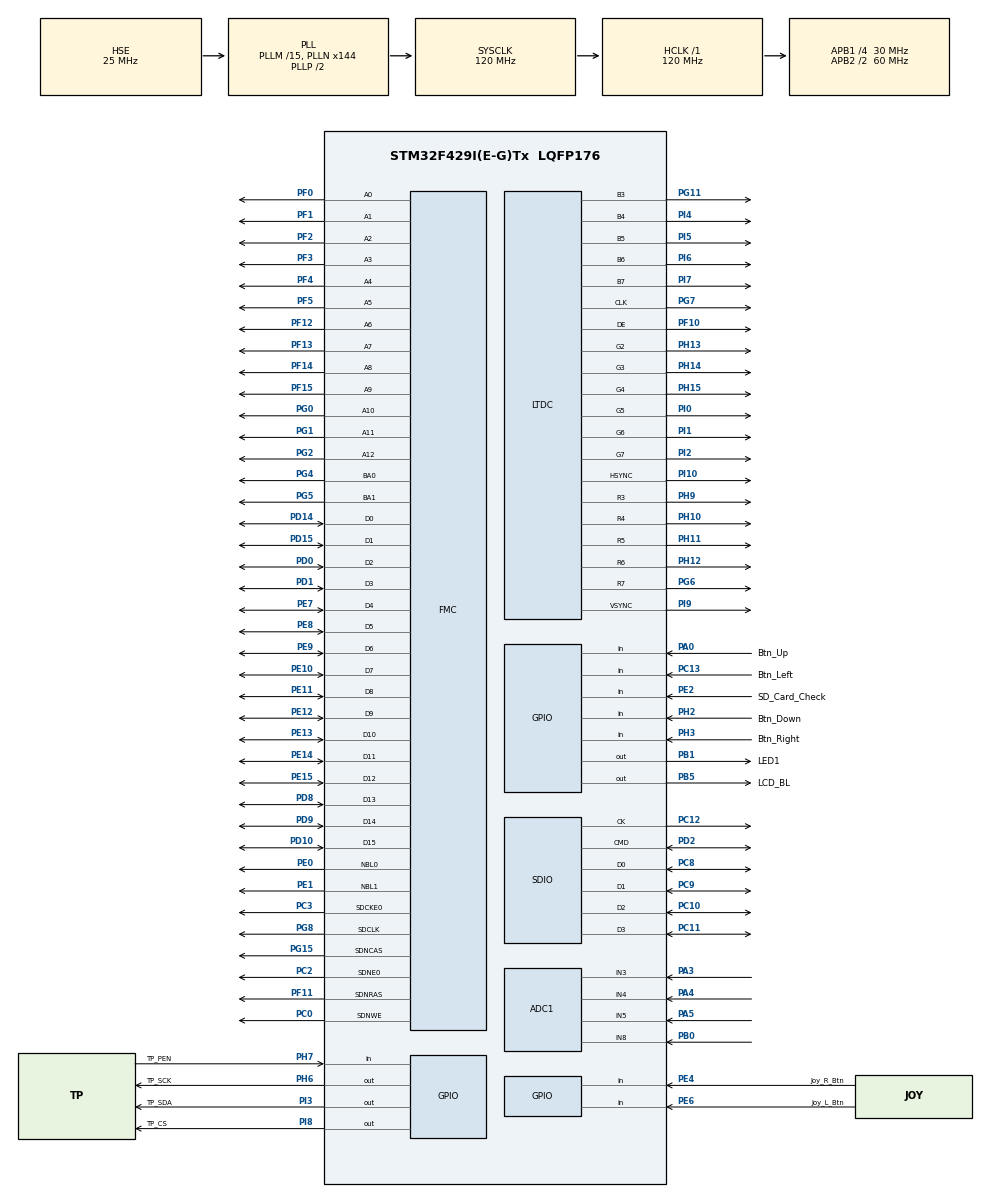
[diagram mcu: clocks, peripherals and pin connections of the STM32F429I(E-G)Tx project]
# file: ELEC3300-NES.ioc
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ADC1.Channel-1\#ChannelRegularConversion=ADC_CHANNEL_3
ADC1.ContinuousConvMode=DISABLE
ADC1.NbrOfConversionFlag=1
ADC1.Rank-1\#ChannelRegularConversion=1
ADC1.SamplingTime-1\#ChannelRegularConversion=ADC_SAMPLETIME_3CYCLES
ADC1.master=1
DMA2D.ColorMode=DMA2D_OUTPUT_RGB565
DMA2D.Mode=DMA2D_R2M
Dma.Request0=SDIO
Dma.SDIO.0.Direction=DMA_PERIPH_TO_MEMORY
Dma.SDIO.0.FIFOMode=DMA_FIFOMODE_ENABLE
Dma.SDIO.0.FIFOThreshold=DMA_FIFO_THRESHOLD_FULL
Dma.SDIO.0.Instance=DMA2_Stream3
Dma.SDIO.0.MemBurst=DMA_MBURST_INC4
Dma.SDIO.0.MemDataAlignment=DMA_MDATAALIGN_WORD
Dma.SDIO.0.MemInc=DMA_MINC_ENABLE
Dma.SDIO.0.Mode=DMA_PFCTRL
Dma.SDIO.0.PeriphBurst=DMA_PBURST_INC4
Dma.SDIO.0.PeriphDataAlignment=DMA_PDATAALIGN_WORD
Dma.SDIO.0.PeriphInc=DMA_PINC_DISABLE
Dma.SDIO.0.Priority=DMA_PRIORITY_LOW
FATFS.BSP.number=1
FATFS._CODE_PAGE=950
FATFS._USE_LFN=2
FATFS._VOLUMES=2
FATFS0.BSP.STBoard=false
FATFS0.BSP.api=Unknown
FATFS0.BSP.instance=PE2
FATFS0.BSP.ip=GPIO
FATFS0.BSP.mode=Input
FATFS0.BSP.name=Detect_SDIO
FATFS0.BSP.solution=PE2
FMC.CASLatency1=FMC_SDRAM_CAS_LATENCY_3
FMC.ColumnBitsNumber1=FMC_SDRAM_COLUMN_BITS_NUM_9
FMC.ExitSelfRefreshDelay1=8
FMC.LoadToActiveDelay1=2
FMC.RCDDelay1=2
FMC.RPDelay1=2
FMC.RPDelay2=2
FMC.ReadBurst1=FMC_SDRAM_RBURST_ENABLE
FMC.ReadBurst2=FMC_SDRAM_RBURST_ENABLE
FMC.ReadPipeDelay1=FMC_SDRAM_RPIPE_DELAY_1
FMC.ReadPipeDelay2=FMC_SDRAM_RPIPE_DELAY_1
FMC.RowCycleDelay1=7
FMC.RowCycleDelay2=7
FMC.SDClockPeriod1=FMC_SDRAM_CLOCK_PERIOD_2
FMC.SDClockPeriod2=FMC_SDRAM_CLOCK_PERIOD_2
FMC.SelfRefreshTime1=6
FMC.WriteRecoveryTime1=5
FREERTOS.Tasks01=defaultTask,24,128,StartDefaultTask,Default,NULL,Dynamic,NULL,NULL
FREERTOS.configUSE_NEWLIB_REENTRANT=1
FREERTOS.configUSE_TICK_HOOK=1
LTDC.ActiveH=600
LTDC.ActiveW=1024
LTDC.Alpha_L0=255
LTDC.FBStartAdress_L0=0xC0000000
LTDC.Green_L0=0
LTDC.HBP=140
LTDC.HFP=160
LTDC.HSync=20
LTDC.ImageHeight_L0=600
LTDC.ImageWidth_L0=1024
LTDC.Layers=0
LTDC.PixelFormat_L0=LTDC_PIXEL_FORMAT_RGB565
LTDC.Red_L1=255
LTDC.VBP=20
LTDC.VFP=12
LTDC.VSync=3
LTDC.WindowX1_L0=1024
LTDC.WindowX1_L1=1024
LTDC.WindowY1_L0=600
LTDC.WindowY1_L1=600
Mcu.Family=STM32F4
Mcu.Name=STM32F429I(E-G)Tx
Mcu.Package=LQFP176
NVIC.DMA2_Stream3_IRQn=true\:5\:0\:true\:false\:true\:true\:false\:true\:true
NVIC.PriorityGroup=NVIC_PRIORITYGROUP_4
NVIC.SDIO_IRQn=true\:6\:0\:true\:false\:true\:true\:true\:true\:true
NVIC.TIM1_UP_TIM10_IRQn=true\:15\:0\:false\:false\:true\:false\:false\:true\:true
NVIC.TimeBase=TIM1_UP_TIM10_IRQn
NVIC.TimeBaseIP=TIM1
PA0/WKUP.GPIO_Label=Btn_Up
PA0/WKUP.Signal=GPIO_Input
PA13.Mode=Serial_Wire
PA13.Signal=SYS_JTMS-SWDIO
PA14.Mode=Serial_Wire
PA14.Signal=SYS_JTCK-SWCLK
PA3.Signal=ADCx_IN3
PA4.Signal=ADCx_IN4
PA5.Signal=ADCx_IN5
PB0.Signal=ADCx_IN8
PB1.GPIO_Label=LED1
PB1.Signal=GPIO_Output
PB5.GPIO_Label=LCD_BL
PB5.GPIO_Speed=GPIO_SPEED_FREQ_HIGH
PB5.Signal=GPIO_Output
PC0.Signal=FMC_SDNWE
PC10.Mode=SD_4_bits_Wide_bus
PC10.Signal=SDIO_D2
PC11.Mode=SD_4_bits_Wide_bus
PC11.Signal=SDIO_D3
PC12.Mode=SD_4_bits_Wide_bus
PC12.Signal=SDIO_CK
PC13.GPIO_Label=Btn_Left
PC13.GPIO_PuPd=GPIO_PULLUP
PC13.Signal=GPIO_Input
PC14/OSC32_IN.Mode=LSE-External-Oscillator
PC14/OSC32_IN.Signal=RCC_OSC32_IN
PC15/OSC32_OUT.Mode=LSE-External-Oscillator
PC15/OSC32_OUT.Signal=RCC_OSC32_OUT
PC2.Mode=SdramChipSelect1_1
PC2.Signal=FMC_SDNE0
PC3.Mode=SdramChipSelect1_1
PC3.Signal=FMC_SDCKE0
PC8.Mode=SD_4_bits_Wide_bus
PC8.Signal=SDIO_D0
PC9.Mode=SD_4_bits_Wide_bus
PC9.Signal=SDIO_D1
PD0.Signal=FMC_D2_DA2
PD1.Signal=FMC_D3_DA3
PD10.Signal=FMC_D15_DA15
PD14.Signal=FMC_D0_DA0
PD15.Signal=FMC_D1_DA1
PD2.Mode=SD_4_bits_Wide_bus
PD2.Signal=SDIO_CMD
PD8.Signal=FMC_D13_DA13
PD9.Signal=FMC_D14_DA14
PE0.Signal=FMC_NBL0
PE1.Signal=FMC_NBL1
PE10.Signal=FMC_D7_DA7
PE11.Signal=FMC_D8_DA8
PE12.Signal=FMC_D9_DA9
PE13.Signal=FMC_D10_DA10
PE14.Signal=FMC_D11_DA11
PE15.Signal=FMC_D12_DA12
PE2.GPIO_Label=SD_Card_Check
PE2.Signal=GPIO_Input
PE4.GPIO_Label=Joy_R_Btn
PE4.Signal=GPIO_Input
PE6.GPIO_Label=Joy_L_Btn
PE6.Signal=GPIO_Input
PE7.Signal=FMC_D4_DA4
PE8.Signal=FMC_D5_DA5
PE9.Signal=FMC_D6_DA6
PF0.Signal=FMC_A0
PF1.Signal=FMC_A1
PF10.GPIO_Speed=GPIO_SPEED_FREQ_VERY_HIGH
PF10.Mode=RGB565
PF10.Signal=LTDC_DE
PF11.Signal=FMC_SDNRAS
PF12.Signal=FMC_A6
PF13.Signal=FMC_A7
PF14.Signal=FMC_A8
PF15.Signal=FMC_A9
PF2.Signal=FMC_A2
PF3.Signal=FMC_A3
PF4.Signal=FMC_A4
PF5.Signal=FMC_A5
PG0.Signal=FMC_A10
PG1.Signal=FMC_A11
PG11.GPIO_Speed=GPIO_SPEED_FREQ_VERY_HIGH
PG11.Mode=RGB565
PG11.Signal=LTDC_B3
PG15.Signal=FMC_SDNCAS
PG2.Signal=FMC_A12
PG4.Signal=FMC_A14_BA0
PG5.Signal=FMC_A15_BA1
PG6.GPIO_Speed=GPIO_SPEED_FREQ_VERY_HIGH
PG6.Mode=RGB565
PG6.Signal=LTDC_R7
PG7.GPIO_Speed=GPIO_SPEED_FREQ_VERY_HIGH
PG7.Mode=RGB565
PG7.Signal=LTDC_CLK
PG8.Signal=FMC_SDCLK
PH0/OSC_IN.Mode=HSE-External-Oscillator
PH0/OSC_IN.Signal=RCC_OSC_IN
PH1/OSC_OUT.Mode=HSE-External-Oscillator
PH1/OSC_OUT.Signal=RCC_OSC_OUT
PH10.GPIO_Speed=GPIO_SPEED_FREQ_VERY_HIGH
PH10.Mode=RGB565
PH10.Signal=LTDC_R4
PH11.GPIO_Speed=GPIO_SPEED_FREQ_VERY_HIGH
PH11.Mode=RGB565
PH11.Signal=LTDC_R5
PH12.GPIO_Speed=GPIO_SPEED_FREQ_VERY_HIGH
PH12.Mode=RGB565
PH12.Signal=LTDC_R6
PH13.GPIO_Speed=GPIO_SPEED_FREQ_VERY_HIGH
PH13.Mode=RGB565
PH13.Signal=LTDC_G2
PH14.GPIO_Speed=GPIO_SPEED_FREQ_VERY_HIGH
PH14.Mode=RGB565
PH14.Signal=LTDC_G3
PH15.GPIO_Speed=GPIO_SPEED_FREQ_VERY_HIGH
PH15.Mode=RGB565
PH15.Signal=LTDC_G4
PH2.GPIO_Label=Btn_Down
PH2.GPIO_PuPd=GPIO_PULLUP
PH2.Signal=GPIO_Input
PH3.GPIO_Label=Btn_Right
PH3.GPIO_PuPd=GPIO_PULLUP
PH3.Signal=GPIO_Input
PH6.GPIO_Label=TP_SCK
PH6.GPIO_PuPd=GPIO_PULLUP
PH6.GPIO_Speed=GPIO_SPEED_FREQ_HIGH
PH6.Signal=GPIO_Output
PH7.GPIO_Label=TP_PEN
PH7.Signal=GPIO_Input
PH9.GPIO_Speed=GPIO_SPEED_FREQ_VERY_HIGH
PH9.Mode=RGB565
PH9.Signal=LTDC_R3
PI0.GPIO_Speed=GPIO_SPEED_FREQ_VERY_HIGH
PI0.Mode=RGB565
PI0.Signal=LTDC_G5
PI1.GPIO_Speed=GPIO_SPEED_FREQ_VERY_HIGH
PI1.Mode=RGB565
PI1.Signal=LTDC_G6
PI10.GPIO_Speed=GPIO_SPEED_FREQ_VERY_HIGH
PI10.Mode=RGB565
PI10.Signal=LTDC_HSYNC
PI2.GPIO_Speed=GPIO_SPEED_FREQ_VERY_HIGH
PI2.Mode=RGB565
PI2.Signal=LTDC_G7
PI3.GPIO_Label=TP_SDA
PI3.GPIO_ModeDefaultOutputPP=GPIO_MODE_OUTPUT_OD
PI3.GPIO_PuPd=GPIO_PULLUP
PI3.Signal=GPIO_Output
PI4.GPIO_Speed=GPIO_SPEED_FREQ_VERY_HIGH
PI4.Mode=RGB565
PI4.Signal=LTDC_B4
PI5.GPIO_Speed=GPIO_SPEED_FREQ_VERY_HIGH
PI5.Mode=RGB565
PI5.Signal=LTDC_B5
PI6.GPIO_Speed=GPIO_SPEED_FREQ_VERY_HIGH
PI6.Mode=RGB565
PI6.Signal=LTDC_B6
PI7.GPIO_Speed=GPIO_SPEED_FREQ_VERY_HIGH
PI7.Mode=RGB565
PI7.Signal=LTDC_B7
PI8.GPIO_Label=TP_CS
PI8.GPIO_PuPd=GPIO_PULLUP
PI8.PinState=GPIO_PIN_RESET
PI8.Signal=GPIO_Output
PI9.GPIO_Speed=GPIO_SPEED_FREQ_VERY_HIGH
PI9.Mode=RGB565
PI9.Signal=LTDC_VSYNC
ProjectManager.HeapSize=0x200
ProjectManager.StackSize=0x1000
ProjectManager.TargetToolchain=STM32CubeIDE
RCC.48MHZClocksFreq_Value=48000000
RCC.AHBFreq_Value=120000000
RCC.APB1CLKDivider=RCC_HCLK_DIV4
RCC.APB1Freq_Value=30000000
RCC.APB1TimFreq_Value=60000000
RCC.APB2CLKDivider=RCC_HCLK_DIV2
RCC.APB2Freq_Value=60000000
RCC.APB2TimFreq_Value=120000000
RCC.CortexFreq_Value=120000000
RCC.HCLKFreq_Value=120000000
RCC.HSE_VALUE=25000000
RCC.HSI_VALUE=16000000
RCC.PLLM=15
RCC.PLLN=144
RCC.PLLQ=5
RCC.PLLSAIN=60
RCC.PLLSourceVirtual=RCC_PLLSOURCE_HSE
RCC.SYSCLKFreq_VALUE=120000000
RCC.SYSCLKSource=RCC_SYSCLKSOURCE_PLLCLK
RCC.VCOOutputFreq_Value=240000000
SDIO.HardwareFlowControl=SDIO_HARDWARE_FLOW_CONTROL_ENABLE
SH.ADCx_IN3.0=ADC1_IN3,IN3
SH.ADCx_IN4.0=ADC1_IN4,IN4
SH.ADCx_IN5.0=ADC1_IN5,IN5
SH.ADCx_IN8.0=ADC1_IN8,IN8
SH.FMC_A0.0=FMC_A0,13b-sda1
SH.FMC_A1.0=FMC_A1,13b-sda1
SH.FMC_A10.0=FMC_A10,13b-sda1
SH.FMC_A11.0=FMC_A11,13b-sda1
SH.FMC_A12.0=FMC_A12,13b-sda1
SH.FMC_A14_BA0.0=FMC_BA0,FourSdramBanks1
SH.FMC_A15_BA1.0=FMC_BA1,FourSdramBanks1
SH.FMC_A2.0=FMC_A2,13b-sda1
SH.FMC_A3.0=FMC_A3,13b-sda1
SH.FMC_A4.0=FMC_A4,13b-sda1
SH.FMC_A5.0=FMC_A5,13b-sda1
SH.FMC_A6.0=FMC_A6,13b-sda1
SH.FMC_A7.0=FMC_A7,13b-sda1
SH.FMC_A8.0=FMC_A8,13b-sda1
SH.FMC_A9.0=FMC_A9,13b-sda1
SH.FMC_D0_DA0.0=FMC_D0,sd-16b-d1
SH.FMC_D10_DA10.0=FMC_D10,sd-16b-d1
SH.FMC_D11_DA11.0=FMC_D11,sd-16b-d1
SH.FMC_D12_DA12.0=FMC_D12,sd-16b-d1
SH.FMC_D13_DA13.0=FMC_D13,sd-16b-d1
SH.FMC_D14_DA14.0=FMC_D14,sd-16b-d1
SH.FMC_D15_DA15.0=FMC_D15,sd-16b-d1
SH.FMC_D1_DA1.0=FMC_D1,sd-16b-d1
SH.FMC_D2_DA2.0=FMC_D2,sd-16b-d1
SH.FMC_D3_DA3.0=FMC_D3,sd-16b-d1
SH.FMC_D4_DA4.0=FMC_D4,sd-16b-d1
SH.FMC_D5_DA5.0=FMC_D5,sd-16b-d1
SH.FMC_D6_DA6.0=FMC_D6,sd-16b-d1
SH.FMC_D7_DA7.0=FMC_D7,sd-16b-d1
SH.FMC_D8_DA8.0=FMC_D8,sd-16b-d1
SH.FMC_D9_DA9.0=FMC_D9,sd-16b-d1
SH.FMC_NBL0.0=FMC_NBL0,Sd2ByteEnable1
SH.FMC_NBL1.0=FMC_NBL1,Sd2ByteEnable1
SH.FMC_SDCLK.0=FMC_SDCLK,13b-sda1
SH.FMC_SDNCAS.0=FMC_SDNCAS,13b-sda1
SH.FMC_SDNRAS.0=FMC_SDNRAS,13b-sda1
SH.FMC_SDNWE.0=FMC_SDNWE,13b-sda1
VP_DMA2D_VS_DMA2D.Mode=DMA2D_Activate
VP_FATFS_VS_FMC_SDRAM.Mode=FMC_SDRAM
VP_FATFS_VS_SDIO.Mode=SDIO
VP_FREERTOS_VS_CMSIS_V2.Mode=CMSIS_V2
VP_SYS_VS_tim1.Mode=TIM1
board=custom

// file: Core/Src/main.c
/* USER CODE BEGIN Header */
/**
 ******************************************************************************
 * @file           : main.c
 * @brief          : Main program body
 ******************************************************************************
 * @attention
 *
 * Copyright (c) 2023 STMicroelectronics.
 * All rights reserved.
 *
 * This software is licensed under terms that can be found in the LICENSE file
 * in the root directory of this software component.
 * If no LICENSE file comes with this software, it is provided AS-IS.
 *
 ******************************************************************************
 */
/* USER CODE END Header */
#include "main.h"

#include "adc.h"
#include "cmsis_os.h"
#include "dma.h"
#include "dma2d.h"
#include "fatfs.h"
#include "fmc.h"
#include "gpio.h"
#include "ltdc.h"
#include "sdio.h"

/* USER CODE BEGIN Includes */
#include "user/board.h"
#include "user/nes/InfoNES.h"
#include "user/nes/InfoNES_System.h"
#include "user/os.h"

/* USER CODE END Includes */

void SystemClock_Config(void);
void MX_FREERTOS_Init(void);

/* USER CODE BEGIN 0 */

DEFINE_THREAD(led_task, led_blinky);

void led_blinky(void* par) {
	uint32_t last_ticks = 0;

	while (1) {
		osDelay(4);
		if (HAL_GetTick() - last_ticks >= 100) {
			gpio_toggle(LED1);
			last_ticks = HAL_GetTick();
		}
	}
}

/* USER CODE END 0 */

int main(void) {

	/* MCU Configuration--------------------------------------------------------*/

	/* Reset of all peripherals, Initializes the Flash interface and the Systick. */
	HAL_Init();

	/* Configure the system clock */
	SystemClock_Config();

	/* Initialize all configured peripherals */
	MX_GPIO_Init();
	MX_DMA_Init();
	MX_LTDC_Init();
	MX_FMC_Init();
	MX_DMA2D_Init();
	MX_ADC1_Init();
	MX_SDIO_SD_Init();
	MX_FATFS_Init();
	/* USER CODE BEGIN 2 */

	nesStart();

	/* USER CODE END 2 */

	/* Init scheduler */
	osKernelInitialize(); /* Call init function for freertos objects (in freertos.c) */
	MX_FREERTOS_Init();

	os_create_thread(led_task, NULL, 4);

	/* Start scheduler */
	osKernelStart();

	/* We should never get here as control is now taken by the scheduler */
	/* Infinite loop */
	while (1) {

	}
}

void SystemClock_Config(void) {
	RCC_OscInitTypeDef RCC_OscInitStruct = {0};
	RCC_ClkInitTypeDef RCC_ClkInitStruct = {0};

	/** Configure the main internal regulator output voltage
	 */
	__HAL_RCC_PWR_CLK_ENABLE();
	__HAL_PWR_VOLTAGESCALING_CONFIG(PWR_REGULATOR_VOLTAGE_SCALE3);

	/** Initializes the RCC Oscillators according to the specified parameters
	 * in the RCC_OscInitTypeDef structure.
	 */
	RCC_OscInitStruct.OscillatorType = RCC_OSCILLATORTYPE_HSE;
	RCC_OscInitStruct.HSEState = RCC_HSE_ON;
	RCC_OscInitStruct.PLL.PLLState = RCC_PLL_ON;
	RCC_OscInitStruct.PLL.PLLSource = RCC_PLLSOURCE_HSE;
	RCC_OscInitStruct.PLL.PLLM = 15;
	RCC_OscInitStruct.PLL.PLLN = 144;
	RCC_OscInitStruct.PLL.PLLP = RCC_PLLP_DIV2;
	RCC_OscInitStruct.PLL.PLLQ = 5;
	if (HAL_RCC_OscConfig(&RCC_OscInitStruct) != HAL_OK) {
		Error_Handler();
	}

	/** Initializes the CPU, AHB and APB buses clocks
	 */
	RCC_ClkInitStruct.ClockType = RCC_CLOCKTYPE_HCLK | RCC_CLOCKTYPE_SYSCLK | RCC_CLOCKTYPE_PCLK1 | RCC_CLOCKTYPE_PCLK2;
	RCC_ClkInitStruct.SYSCLKSource = RCC_SYSCLKSOURCE_PLLCLK;
	RCC_ClkInitStruct.AHBCLKDivider = RCC_SYSCLK_DIV1;
	RCC_ClkInitStruct.APB1CLKDivider = RCC_HCLK_DIV4;
	RCC_ClkInitStruct.APB2CLKDivider = RCC_HCLK_DIV2;

	if (HAL_RCC_ClockConfig(&RCC_ClkInitStruct, FLASH_LATENCY_3) != HAL_OK) {
		Error_Handler();
	}
}

void HAL_TIM_PeriodElapsedCallback(TIM_HandleTypeDef* htim) {
	if (htim->Instance == TIM1) {
		HAL_IncTick();
	}
}

void Error_Handler(void) {
	__disable_irq();
	while (1) {}
}

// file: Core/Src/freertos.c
/* USER CODE BEGIN Header */
/**
  ******************************************************************************
  * File Name          : freertos.c
  * Description        : Code for freertos applications
  ******************************************************************************
  * @attention
  *
  * Copyright (c) 2023 STMicroelectronics.
  * All rights reserved.
  *
  * This software is licensed under terms that can be found in the LICENSE file
  * in the root directory of this software component.
  * If no LICENSE file comes with this software, it is provided AS-IS.
  *
  ******************************************************************************
  */
/* USER CODE END Header */

#include "FreeRTOS.h"
#include "task.h"
#include "main.h"
#include "cmsis_os.h"

/* Definitions for defaultTask */
osThreadId_t defaultTaskHandle;
const osThreadAttr_t defaultTask_attributes = {
  .name = "defaultTask",
  .stack_size = 128 * 4,
  .priority = (osPriority_t) osPriorityNormal,
};

void StartDefaultTask(void *argument);

void MX_FREERTOS_Init(void); /* (MISRA C 2004 rule 8.1) */

/* Hook prototypes */
void vApplicationTickHook(void);

/* USER CODE BEGIN 3 */
void vApplicationTickHook( void )
{
   /* This function will be called by each tick interrupt if
   configUSE_TICK_HOOK is set to 1 in FreeRTOSConfig.h. User code can be
   added here, but the tick hook is called from an interrupt context, so
   code must not attempt to block, and only the interrupt safe FreeRTOS API
   functions can be used (those that end in FromISR()). */
}
/* USER CODE END 3 */

void MX_FREERTOS_Init(void) {

  /* Create the thread(s) */
  /* creation of defaultTask */
  defaultTaskHandle = osThreadNew(StartDefaultTask, NULL, &defaultTask_attributes);

}

void StartDefaultTask(void *argument)
{
  for(;;)
  {
    osDelay(1);
  }
}
